# MKL28T7_CORE1 register map
Vendor: Freescale Semiconductor, Inc.; Series: Kinetis_L; File version: 1.6
CPU: CM0PLUS r0p0, little endian, no MPU, no FPU, VTOR, 2 interrupt priority bits
Registers are 32-bit, read-write, reset 0x0 unless marked. A register's access mark holds for its fields unless they carry their own. Offsets are from the block's base; [hi:lo] are bit positions; {n}, {i} and the like mark numbered series.

## MU0_A — MU
Base 0x40023000; register names take the prefix MU0_A_
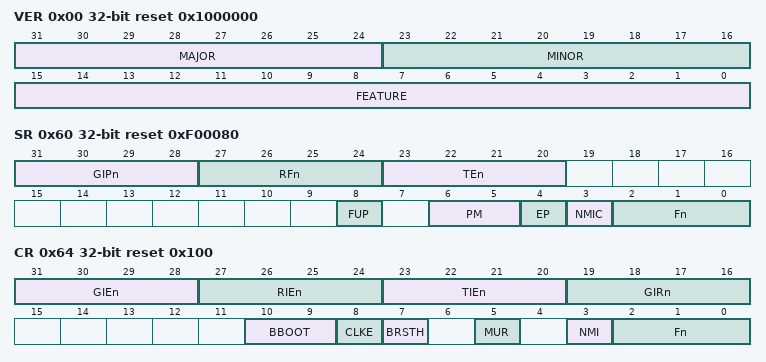
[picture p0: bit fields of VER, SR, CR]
0x00 VER ro reset 0x1000000 — Version ID Register
  [31:24] MAJOR — Major Version Number
  [23:16] MINOR — Minor Version Number
  [15:0] FEATURE — Feature Specification Number
{0x20+4i} TR{i} (i=0..3) — Transmit Register
  [31:0] DATA — Processor A/B Transmit Register Data
{0x40+4i} RR{i} (i=0..3) ro — Receive Register
  [31:0] DATA — Processor A/B Receive Register
0x60 SR reset 0xF00080 — Status Register
  [31:28] GIPn — For n = {0, 1, 2, 3} Processor A/B General Interrupt Request n Pending
    0=Processor A/B general purpose interrupt n is not pending. (default); 1=Processor A/B general purpose interrupt n is pending
  [27:24] RFn — For n = {0, 1, 2, 3} Processor A/B Receive Register n Full
    0=Processor A/B RRn register is not full (default); 1=Processor A/B RRn register has received data from Processor B/A TRn register and is ready to be read by the Processor A/B
  [23:20] TEn — For n = {0, 1, 2, 3} Processor A/B Transmit Register n Empty
    0=Processor A/B TRn register is not empty; 1=Processor A/B TRn register is empty (default)
  [8] FUP — Processor A/B Flags Update Pending
    0=No flags updated, initiated by the Processor A, in progress (default); 1=Processor A/B initiated flags update, processing
  [6:5] PM — Processor B/A Power Mode
    0=The Processor B/A is in Run Mode; 1=The Processor B/A is in WAIT Mode; 2=The Processor B/A is in STOP/VLPS Mode; 3=The Processor B/A is in LLS/VLLS Mode
  [4] EP — Processor A/B Side Event Pending
    0=The Processor A-side event is not pending (default); 1=The Processor A-side event is pending
  [3] NMIC — Processor A/B Non-Maskable-Interrupt Clear
    0=Default; 1=Writing "1" clears the NMI bit in the BCR register
  [2:0] Fn — For n = {0, 1, 2} Processor A/B Side Flag n
    0=Processor B/A Fn bit in the CR register is written 0 (default); 1=Processor B/A Fn bit in the CR register is written 1
0x64 CR reset 0x100 — Control Register
  [31:28] GIEn — For n = {0, 1, 2, 3} Processor A/B General Purpose Interrupt Enable n
    0=Disables Processor A/B General Interrupt n. (default); 1=Enables Processor A/B General Interrupt n
  [27:24] RIEn — For n = {0, 1, 2, 3} Processor A/B Receive Interrupt Enable n
    0=Disables Processor A/B Receive Interrupt n. (default); 1=Enables Processor A/B Receive Interrupt n
  [23:20] TIEn — For n = {0, 1, 2, 3} Processor A/B Transmit Interrupt Enable n
    0=Disables Processor A/B Transmit Interrupt n. (default); 1=Enables Processor A/B Transmit Interrupt n
  [19:16] GIRn — For n = {0, 1, 2, 3} Processor A/B General Purpose Interrupt Request n
    0=Processor A/B General Interrupt n is not requested to the Processor B/A (default); 1=Processor A/B General Interrupt n is requested to the Processor B/A
  [10:9] BBOOT — Processor B Boot Config.
    0=Boot from 0x0; 1=Boot from DMEM Base; 2=Boot from IMEM Base
  [8] CLKE — Processor B/A clock enable
    0=Processor B/A platform clock gated when Processor B/A enters a stop mode; 1=Processor B/A platform clock kept running after Processor B/A enters a stop mode, until Processor A/B also enters a stop mode
  [7] BRSTH — Processor B Reset Hold
    0=Release Processor B from reset; 1=Hold Processor B in reset
  [5] MUR — Processor A MU Reset
    0=N/A. Self clearing bit (default).; 1=Asserts the Processor A MU reset
  [3] NMI — Processor B/A Non-maskable Interrupt
    0=Non-maskable interrupt is not issued to the Processor B/A by the Processor A/B (default); 1=Non-maskable interrupt is issued to the Processor B/A by the Processor A/B
  [2:0] Fn — For n = {0, 1, 2} Processor A/B to Processor B/A Flag n
    0=Clears the Fn bit in the SR register; 1=Sets the Fn bit in the SR register

## MU0_B — MU
Base 0x400A3000; register names take the prefix MU0_B_
Registers as MU0_A.
